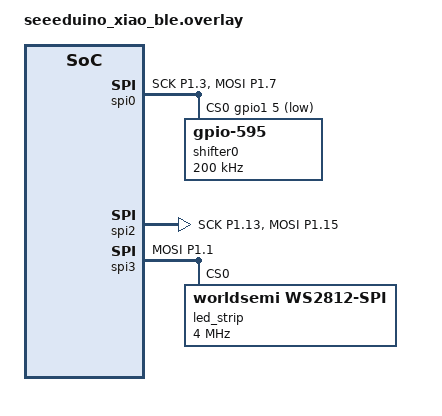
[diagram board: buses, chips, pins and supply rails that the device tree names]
/**
 * Generated by Shield Wizard for ZMK
 * Applies to part "right" with controller "xiao_ble_plus"
 */

// pin control for spi0
// - SCK on D17
// - MOSI on D19
&pinctrl {
    /* configuration for spi0 device, default state */
    spi0_default: spi0_default {
        group1 {
            psels = <NRF_PSEL(SPIM_SCK, 1, 3)>,
                    <NRF_PSEL(SPIM_MOSI, 1, 7)>;
        };
    };
    /* configuration for spi0 device, sleep state */
    spi0_sleep: spi0_sleep {
        group1 {
            psels = <NRF_PSEL(SPIM_SCK, 1, 3)>,
                    <NRF_PSEL(SPIM_MOSI, 1, 7)>;
            low-power-enable;
        };
    };
};
&spi0 {
    compatible = "nordic,nrf-spim";
    status = "okay";
    pinctrl-0 = <&spi0_default>;
    pinctrl-1 = <&spi0_sleep>;
    pinctrl-names = "default", "sleep";
};

// devices on spi0

// CS pins for devices on spi0
&spi0 {
    cs-gpios = <&gpio1 5 GPIO_ACTIVE_LOW>;
};

&spi0 {
    shifter0: 595@0 {
        compatible = "zmk,gpio-595";
        reg = <0>;
        status = "okay";
        gpio-controller;
        spi-max-frequency = <200000>;
        #gpio-cells = <2>;
        ngpios = <8>;
    };
};

// pin control for spi2
// - SCK on D8
// - MOSI on D10
&pinctrl {
    /* configuration for spi2 device, default state */
    spi2_default: spi2_default {
        group1 {
            psels = <NRF_PSEL(SPIM_SCK, 1, 13)>,
                    <NRF_PSEL(SPIM_MOSI, 1, 15)>;
        };
    };
    /* configuration for spi2 device, sleep state */
    spi2_sleep: spi2_sleep {
        group1 {
            psels = <NRF_PSEL(SPIM_SCK, 1, 13)>,
                    <NRF_PSEL(SPIM_MOSI, 1, 15)>;
            low-power-enable;
        };
    };
};
&spi2 {
    compatible = "nordic,nrf-spim";
    status = "okay";
    pinctrl-0 = <&spi2_default>;
    pinctrl-1 = <&spi2_sleep>;
    pinctrl-names = "default", "sleep";
};

// devices on spi2

// CS pins for devices on spi2
&spi2 {
    cs-gpios = <&xiao_d 9 GPIO_ACTIVE_HIGH>;
};

nice_view_spi: &spi2 { };

// pin control for spi3
// - MOSI on D13
&pinctrl {
    /* configuration for spi3 device, default state */
    spi3_default: spi3_default {
        group1 {
            psels = <NRF_PSEL(SPIM_MOSI, 1, 1)>;
        };
    };
    /* configuration for spi3 device, sleep state */
    spi3_sleep: spi3_sleep {
        group1 {
            psels = <NRF_PSEL(SPIM_MOSI, 1, 1)>;
            low-power-enable;
        };
    };
};
&spi3 {
    compatible = "nordic,nrf-spim";
    status = "okay";
    pinctrl-0 = <&spi3_default>;
    pinctrl-1 = <&spi3_sleep>;
    pinctrl-names = "default", "sleep";
};

// devices on spi3

#include <dt-bindings/led/led.h>
&spi3 {
    led_strip: ws2812@0 {
        compatible = "worldsemi,ws2812-spi";
        reg = <0>;
        spi-max-frequency = <4000000>;

        chain-length = <19>;
        spi-one-frame = <0x70>;
        spi-zero-frame = <0x40>;
        color-mapping = <LED_COLOR_ID_GREEN
                         LED_COLOR_ID_RED
                         LED_COLOR_ID_BLUE>;
    };
};
/ {
    chosen {
        zmk,underglow = &led_strip;
    };
};
